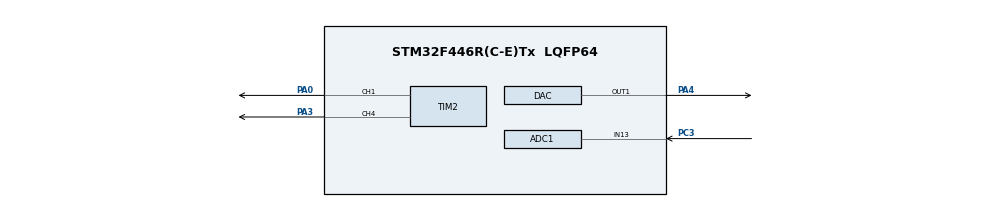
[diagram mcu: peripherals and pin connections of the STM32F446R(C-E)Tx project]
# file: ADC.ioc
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ADC1.Channel-1\#ChannelRegularConversion=ADC_CHANNEL_13
ADC1.ContinuousConvMode=DISABLE
ADC1.DMAContinuousRequests=DISABLE
ADC1.ExternalTrigConv=ADC_EXTERNALTRIGCONV_T2_TRGO
ADC1.NbrOfConversionFlag=1
ADC1.Rank-1\#ChannelRegularConversion=1
ADC1.SamplingTime-1\#ChannelRegularConversion=ADC_SAMPLETIME_480CYCLES
ADC1.ScanConvMode=DISABLE
ADC1.master=1
Dma.ADC1.0.Direction=DMA_PERIPH_TO_MEMORY
Dma.ADC1.0.FIFOMode=DMA_FIFOMODE_DISABLE
Dma.ADC1.0.Instance=DMA2_Stream0
Dma.ADC1.0.MemDataAlignment=DMA_MDATAALIGN_HALFWORD
Dma.ADC1.0.MemInc=DMA_MINC_ENABLE
Dma.ADC1.0.Mode=DMA_CIRCULAR
Dma.ADC1.0.PeriphDataAlignment=DMA_PDATAALIGN_HALFWORD
Dma.ADC1.0.PeriphInc=DMA_PINC_DISABLE
Dma.ADC1.0.Priority=DMA_PRIORITY_LOW
Dma.Request0=ADC1
Mcu.Family=STM32F4
Mcu.Name=STM32F446R(C-E)Tx
Mcu.Package=LQFP64
NVIC.DMA2_Stream0_IRQn=true\:0\:0\:false\:false\:true\:false\:true\:true
NVIC.PriorityGroup=NVIC_PRIORITYGROUP_4
PA0-WKUP.Signal=S_TIM2_CH1_ETR
PA1.Signal=ADCx_IN1
PA3.Signal=S_TIM2_CH4
PA4.Signal=COMP_DAC1_group
PC3.Signal=ADCx_IN13
ProjectManager.HeapSize=0x200
ProjectManager.StackSize=0x400
ProjectManager.TargetToolchain=STM32CubeIDE
RCC.CortexFreq_Value=16000000
RCC.USBFreq_Value=96000000
RCC.VCOOutputFreq_Value=192000000
SH.ADCx_IN1.0=ADC1_IN1
SH.ADCx_IN13.0=ADC1_IN13,IN13
SH.COMP_DAC1_group.0=DAC_OUT1,DAC_OUT1
SH.S_TIM2_CH1_ETR.0=TIM2_CH1,PWM Generation1 CH1
SH.S_TIM2_CH4.0=TIM2_CH4,PWM Generation4 CH4
TIM2.Channel-PWM\ Generation1\ CH1=TIM_CHANNEL_1
TIM2.Channel-PWM\ Generation4\ CH4=TIM_CHANNEL_4
TIM2.TIM_MasterOutputTrigger=TIM_TRGO_UPDATE
VP_TIM2_VS_ClockSourceINT.Mode=Internal
board=custom

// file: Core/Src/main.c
/* USER CODE BEGIN Header */
/**
  ******************************************************************************
  * @file           : main.c
  * @brief          : Main program body
  ******************************************************************************
  * @attention
  *
  * Copyright (c) 2023 STMicroelectronics.
  * All rights reserved.
  *
  * This software is licensed under terms that can be found in the LICENSE file
  * in the root directory of this software component.
  * If no LICENSE file comes with this software, it is provided AS-IS.
  *
  ******************************************************************************
  */
/* USER CODE END Header */
#include "main.h"

ADC_HandleTypeDef hadc1;
DMA_HandleTypeDef hdma_adc1;

DAC_HandleTypeDef hdac;

TIM_HandleTypeDef htim2;

void SystemClock_Config(void);
static void MX_GPIO_Init(void);
static void MX_DMA_Init(void);
static void MX_ADC1_Init(void);
static void MX_DAC_Init(void);
static void MX_TIM2_Init(void);

int main(void)
{

  /* MCU Configuration--------------------------------------------------------*/

  /* Reset of all peripherals, Initializes the Flash interface and the Systick. */
  HAL_Init();

  /* Configure the system clock */
  SystemClock_Config();

  /* Initialize all configured peripherals */
  MX_GPIO_Init();
  MX_DMA_Init();
  MX_ADC1_Init();
  MX_DAC_Init();
  MX_TIM2_Init();
  /* USER CODE BEGIN 2 */
  //HAL_ADCEx_Calibration_Start();
  HAL_ADC_Start_DMA(&hadc1);
  /* USER CODE END 2 */

  /* Infinite loop */
  while (1)
  {
	  HAL_ADC_Start(&hadc1);
	  if(HAL_ADC_PollForConversion(&hadc1, 1000) == HAL_OK)
	  {
		  uint32_t analog_value = HAL_ADC_GetValue(&hadc1);
	  }
	  HAL_ADC_Stop(&hadc1);
  }
}

void SystemClock_Config(void)
{
  RCC_OscInitTypeDef RCC_OscInitStruct = {0};
  RCC_ClkInitTypeDef RCC_ClkInitStruct = {0};

  /** Configure the main internal regulator output voltage
  */
  __HAL_RCC_PWR_CLK_ENABLE();
  __HAL_PWR_VOLTAGESCALING_CONFIG(PWR_REGULATOR_VOLTAGE_SCALE3);

  /** Initializes the RCC Oscillators according to the specified parameters
  * in the RCC_OscInitTypeDef structure.
  */
  RCC_OscInitStruct.OscillatorType = RCC_OSCILLATORTYPE_HSI;
  RCC_OscInitStruct.HSIState = RCC_HSI_ON;
  RCC_OscInitStruct.HSICalibrationValue = RCC_HSICALIBRATION_DEFAULT;
  RCC_OscInitStruct.PLL.PLLState = RCC_PLL_NONE;
  if (HAL_RCC_OscConfig(&RCC_OscInitStruct) != HAL_OK)
  {
    Error_Handler();
  }

  /** Initializes the CPU, AHB and APB buses clocks
  */
  RCC_ClkInitStruct.ClockType = RCC_CLOCKTYPE_HCLK|RCC_CLOCKTYPE_SYSCLK
                              |RCC_CLOCKTYPE_PCLK1|RCC_CLOCKTYPE_PCLK2;
  RCC_ClkInitStruct.SYSCLKSource = RCC_SYSCLKSOURCE_HSI;
  RCC_ClkInitStruct.AHBCLKDivider = RCC_SYSCLK_DIV1;
  RCC_ClkInitStruct.APB1CLKDivider = RCC_HCLK_DIV1;
  RCC_ClkInitStruct.APB2CLKDivider = RCC_HCLK_DIV1;

  if (HAL_RCC_ClockConfig(&RCC_ClkInitStruct, FLASH_LATENCY_0) != HAL_OK)
  {
    Error_Handler();
  }
}

static void MX_ADC1_Init(void)
{

  ADC_ChannelConfTypeDef sConfig = {0};

  /** Configure the global features of the ADC (Clock, Resolution, Data Alignment and number of conversion)
  */
  hadc1.Instance = ADC1;
  hadc1.Init.ClockPrescaler = ADC_CLOCK_SYNC_PCLK_DIV2;
  hadc1.Init.Resolution = ADC_RESOLUTION_12B;
  hadc1.Init.ScanConvMode = DISABLE;
  hadc1.Init.ContinuousConvMode = DISABLE;
  hadc1.Init.DiscontinuousConvMode = DISABLE;
  hadc1.Init.ExternalTrigConvEdge = ADC_EXTERNALTRIGCONVEDGE_RISING;
  hadc1.Init.ExternalTrigConv = ADC_EXTERNALTRIGCONV_T2_TRGO;
  hadc1.Init.DataAlign = ADC_DATAALIGN_RIGHT;
  hadc1.Init.NbrOfConversion = 1;
  hadc1.Init.DMAContinuousRequests = DISABLE;
  hadc1.Init.EOCSelection = ADC_EOC_SINGLE_CONV;
  if (HAL_ADC_Init(&hadc1) != HAL_OK)
  {
    Error_Handler();
  }

  /** Configure for the selected ADC regular channel its corresponding rank in the sequencer and its sample time.
  */
  sConfig.Channel = ADC_CHANNEL_13;
  sConfig.Rank = 1;
  sConfig.SamplingTime = ADC_SAMPLETIME_480CYCLES;
  if (HAL_ADC_ConfigChannel(&hadc1, &sConfig) != HAL_OK)
  {
    Error_Handler();
  }

}

static void MX_DAC_Init(void)
{

  DAC_ChannelConfTypeDef sConfig = {0};

  /** DAC Initialization
  */
  hdac.Instance = DAC;
  if (HAL_DAC_Init(&hdac) != HAL_OK)
  {
    Error_Handler();
  }

  /** DAC channel OUT1 config
  */
  sConfig.DAC_Trigger = DAC_TRIGGER_NONE;
  sConfig.DAC_OutputBuffer = DAC_OUTPUTBUFFER_ENABLE;
  if (HAL_DAC_ConfigChannel(&hdac, &sConfig, DAC_CHANNEL_1) != HAL_OK)
  {
    Error_Handler();
  }

}

static void MX_TIM2_Init(void)
{

  TIM_ClockConfigTypeDef sClockSourceConfig = {0};
  TIM_MasterConfigTypeDef sMasterConfig = {0};
  TIM_OC_InitTypeDef sConfigOC = {0};

  htim2.Instance = TIM2;
  htim2.Init.Prescaler = 0;
  htim2.Init.CounterMode = TIM_COUNTERMODE_UP;
  htim2.Init.Period = 4294967295;
  htim2.Init.ClockDivision = TIM_CLOCKDIVISION_DIV1;
  htim2.Init.AutoReloadPreload = TIM_AUTORELOAD_PRELOAD_DISABLE;
  if (HAL_TIM_Base_Init(&htim2) != HAL_OK)
  {
    Error_Handler();
  }
  sClockSourceConfig.ClockSource = TIM_CLOCKSOURCE_INTERNAL;
  if (HAL_TIM_ConfigClockSource(&htim2, &sClockSourceConfig) != HAL_OK)
  {
    Error_Handler();
  }
  if (HAL_TIM_PWM_Init(&htim2) != HAL_OK)
  {
    Error_Handler();
  }
  sMasterConfig.MasterOutputTrigger = TIM_TRGO_UPDATE;
  sMasterConfig.MasterSlaveMode = TIM_MASTERSLAVEMODE_DISABLE;
  if (HAL_TIMEx_MasterConfigSynchronization(&htim2, &sMasterConfig) != HAL_OK)
  {
    Error_Handler();
  }
  sConfigOC.OCMode = TIM_OCMODE_PWM1;
  sConfigOC.Pulse = 0;
  sConfigOC.OCPolarity = TIM_OCPOLARITY_HIGH;
  sConfigOC.OCFastMode = TIM_OCFAST_DISABLE;
  if (HAL_TIM_PWM_ConfigChannel(&htim2, &sConfigOC, TIM_CHANNEL_1) != HAL_OK)
  {
    Error_Handler();
  }
  if (HAL_TIM_PWM_ConfigChannel(&htim2, &sConfigOC, TIM_CHANNEL_4) != HAL_OK)
  {
    Error_Handler();
  }
  HAL_TIM_MspPostInit(&htim2);

}

static void MX_DMA_Init(void)
{

  /* DMA controller clock enable */
  __HAL_RCC_DMA2_CLK_ENABLE();

  /* DMA interrupt init */
  /* DMA2_Stream0_IRQn interrupt configuration */
  HAL_NVIC_SetPriority(DMA2_Stream0_IRQn, 0, 0);
  HAL_NVIC_EnableIRQ(DMA2_Stream0_IRQn);

}

static void MX_GPIO_Init(void)
{

  /* GPIO Ports Clock Enable */
  __HAL_RCC_GPIOC_CLK_ENABLE();
  __HAL_RCC_GPIOA_CLK_ENABLE();

}

/* USER CODE BEGIN 4 */

static void ADC_DMAConvCplt(DMA_HandleTypeDef *hdma)
{
	//
}

/* USER CODE END 4 */

void Error_Handler(void)
{
  __disable_irq();
  while (1)
  {
  }
}
